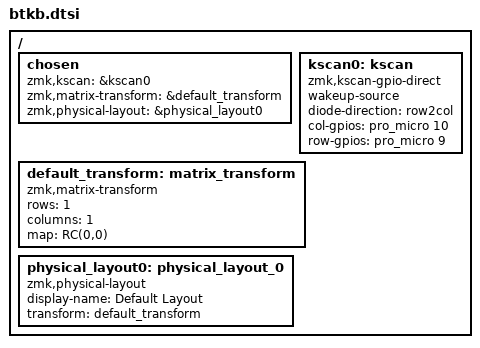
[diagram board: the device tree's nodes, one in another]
#include <dt-bindings/zmk/matrix_transform.h>

/ {
	chosen {
		zmk,kscan = &kscan0;
		zmk,matrix-transform = &default_transform;
		zmk,physical-layout = &physical_layout0;
	};

    kscan0: kscan {
        compatible = "zmk,kscan-gpio-direct";
        wakeup-source;

        diode-direction = "row2col";

        col-gpios
            = <&pro_micro 10 (GPIO_ACTIVE_HIGH | GPIO_PULL_DOWN)>
            ;

        row-gpios
            = <&pro_micro 9 (GPIO_ACTIVE_HIGH)>
            ;
    };

	default_transform: matrix_transform {
                compatible = "zmk,matrix-transform";
                rows = <1>;
                columns = <1>;

                map = <RC(0,0)>;

	};

	physical_layout0: physical_layout_0 {
        compatible = "zmk,physical-layout";
        display-name = "Default Layout";
        transform = <&default_transform>;
    };
};
